# WE2_S_NS register map
Vendor: ARM Ltd.; Series: ARMv8.1-M Mainline; File version: 1.0
CPU: CM55 r1p1, little endian, MPU, FPU, double-precision FPU, DSP, VTOR, 3 interrupt priority bits
Registers are 32-bit, read-write, reset 0x0 unless marked. A register's access mark holds for its fields unless they carry their own. Offsets are from the block's base; [hi:lo] are bit positions.

## SYS_ICB — Implementation control block register
Base 0xE000E000
Same registers: SYS_ICB_NS 0xE002E000
0x04 ICTR ro — Interrupt Controller Type Register
  [3:0] INTLINESNUM — Total number of interrupt lines in groups of 32: [0b0000] 0-32 [0b0001] 33-64 [0b0010] 65-96 [0b0011] 97-128 [0b0100] 129-160 [0b0101] 161-192 [0b0110] 193-224 [0b0111] 225-256 [0b1000] 257-288 [0b1001] 289-320 [0b1010] 321-352 [0b1011] 353-384 [0b1100] 385-416 [0b1101] 417-448 [0b1110] 449-480
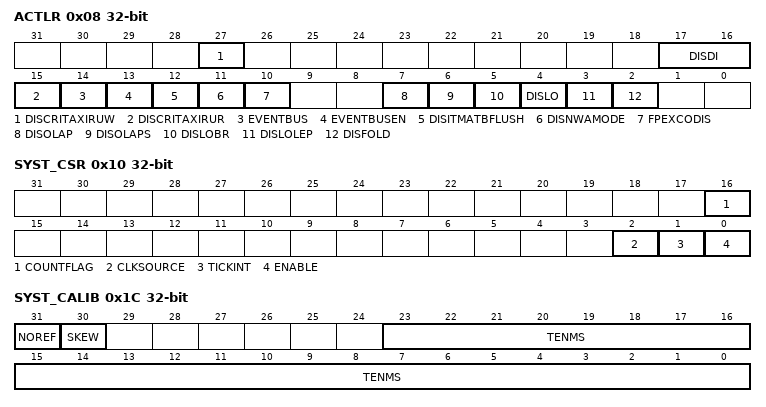
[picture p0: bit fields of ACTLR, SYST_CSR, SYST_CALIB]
0x08 ACTLR — Auxiliary Control Register
  [27] DISCRITAXIRUW — Disable-Critical-AXI-Read-Under-Write: [0] Normal operation. [1] AXI reads to Device memory and exclusive reads to shared memory are not initiated on the M-AXI read address channel until all outstanding writes on the M-AXI interface are complete
  [17:16] DISDI — Disable dual-issue features: [0b00] Full dual-issue, if DISFOLD is set to 0. [0b01] Disable dual-issue of arithmetic instructions. [0b10] Disable lane swapping [0b11] Disable dual-issue of arithmetic instructions and lane swapping
  [15] DISCRITAXIRUR — Disable critical AXI Read-Under-Read [0] Normal operation. [1] AXI reads to Device memory and exclusive reads to shared memory are not initiated on the M-AXI read address channels if there are any outstanding reads on the M-AXI
  [14] EVENTBUS — Activate EVENTBUS output: [0] EVENTBUS not active [1] EVENTBUS active
  [13] EVENTBUSEN — Accessibility of EVENTBUSE: [0] EVENTBUSEN is accessible by both Security state [1] EVENTBUSEN is accessible by Secure state only
  [12] DISITMATBFLUSH — This bit determines whether Instrumentation Trace Macrocell (ITM) or Data Watchpoint and Trace (DWT) ATB flush is disabled. [0] Normal operation. [1] ITM or DWT ATB flush is disabled.
  [11] DISNWAMODE — This bit determines if no write allocate mode is disabled: [0] Normal operation. [1] No write allocate mode is disabled.
  [10] FPEXCODIS — This bit determines if floating-point exception outputs are disabled: [0] Normal operation. [1] Floating-point exception outputs are disabled.
  [7] DISOLAP — Disable overlapping of all instructions
  [6] DISOLAPS — Disable overlapping of scalar-only instructions
  [5] DISLOBR — Disable branch prediction using low overhead loops: [0] Branch prediction enabled. [1] Branch prediction disabled.
  [4] DISLO — Disable low overhead loops: [0] Low overhead loops enabled. [1] Low overhead loops disabled.
  [3] DISLOLEP — Disable end of loop prediction in low overhead loops [0] Low overhead loop end prediction enabled [1] Low overhead loop end prediction disabled
  [2] DISFOLD — This bit determines if dual-issue functionality is disabled: [0] Normal operation. [1] Dual-issue functionality is disabled
0x0C CPPWR — Coprocessor Power Control Register
0x10 SYST_CSR — SysTick Control and Status Register
  [16] COUNTFLAG — Returns 1 if timer counted to 0 since the last read of this register
  [2] CLKSOURCE — Selects the SysTick timer clock source: [0] External reference clock. [1] Processor clock.
  [1] TICKINT — Enables SysTick exception request: [0] Counting down to zero does not assert the SysTick exception request. [1] Counting down to zero asserts the SysTick exception request
  [0] ENABLE — Enables the counter: [0] Counter disabled. [1] Counter enabled.
0x14 SYST_RVR — SysTick Reload Value Register
  [23:0] RELOAD — Value to load into the SYST_CVR when the counter is enabled and when it reaches 0
0x18 SYST_CVR — SysTick Current Value Register
  [23:0] CURRENT — Reads the current value of the SysTick counter. A write of any value clears the field to 0, and also clears the SYST_CSR.COUNTFLAG bit to 0
0x1C SYST_CALIB — SysTick Calibration Value Register
  [31] NOREF — Indicates whether the device provides a reference clock to the processor: [0] Reference clock is implemented, and implies which clock source is described by SKEW and TENMS. [1] Indicates that no separate reference clock is provided.
  [30] SKEW — Indicates whether the TENMS value is exact: [0] Calibration value is exact. [1] Reads as one. Calibration value for the 10ms inexact timing is not known because TENMS is not known. This can affect the suitability of SysTick as a software real-time clock.
  [23:0] TENMS — Reads as zero. Indicates that the calibration value is not known. Optionally holds a reload value to be used for 10ms (100Hz) timing. If NOREF=0, TENMS is the reload value to generate 10ms using the external reference clock. If NOREF=1, TENMS holds the reload value to generate 10ms using the processor clock. If the provided clocks do not allow a consistent 10ms timing period, for example, because the clock speeds change or the SysTick is clock gated or powered down, TENMS should be zero to indicate this
